# NUC029AE_v1 register map
File version: 1.0
Registers are 32-bit, read-write, reset 0x0 unless marked. A register's access mark holds for its fields unless they carry their own. Offsets are from the block's base; [hi:lo] are bit positions; 'fields as' and 'values as' point back to an identical list.

## TMR — TMR Register Map
Base 0x40010000
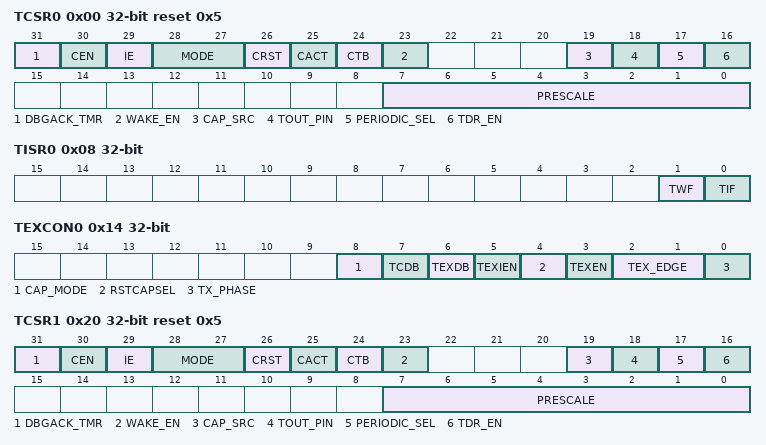
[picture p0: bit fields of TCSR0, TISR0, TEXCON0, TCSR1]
0x00 TCSR0 reset 0x5 — Timer0 Control and Status Register
  [31] DBGACK_TMR — ICE Debug Mode Acknowledge Disable Control (Write Protect). Timer counter will keep going no matter CPU is held by ICE or not.
    0=ICE debug mode acknowledgement effects TIMER counting; 1=ICE debug mode acknowledgement Disabled
  [30] CEN — Timer Enable Control
    0=Stops/Suspends counting; 1=Starts counting
  [29] IE — Interrupt Enable Control. If this bit is enabled, when the timer interrupt flag (TIF) is set to 1, the timer interrupt signal is generated and inform to CPU.
    0=Timer Interrupt function Disabled; 1=Timer Interrupt function Enabled
  [28:27] MODE — Timer Operating Mode
  [26] CRST — Timer Reset
    0=No effect; 1=Reset 8-bit prescale counter, 24-bit up counter value and CEN bit if CACT is 1
  [25] CACT ro — Timer Active Status (Read Only). This bit indicates the 24-bit up counter status.
    0=24-bit up counter is not active; 1=24-bit up counter is active
  [24] CTB — Counter Mode Enable Control. This bit is for external counting pin function enabled. When timer is used as an event counter, this bit should be set to 1 and select HCLK as timer clock source. Please refer to section 6.12.5.3 for detail description.
    0=External event counter mode Disabled; 1=External event counter mode Enabled
  [23] WAKE_EN — Wake-Up Enable Control. When WAKE_EN (UA_IER[6]) is set and the TIF or TEXIF (TEXISR[0]) is set, the timer controller will generator a wake-up trigger event to CPU.
    0=Wake-up trigger event Disabled; 1=Wake-up trigger event Enabled
  [19] CAP_SRC — Capture Pin Source Selection
    0=Capture Function source is from TxEX pin; 1=Capture Function source is from ACMPx output signal
  [18] TOUT_PIN — Toggle Out Pin Selection. When Timer is set to toggle mode,
    0=Time0/1 toggle output pin is T0/T1 pin; 1=Time0/1 toggle output pin is T0EX/T1EX pin
  [17] PERIODIC_SEL — Periodic Mode Behavior Selection
    0=In One-shot or Periodic mode, when write new TCMP, timer counter will reset; 1=In One-shot or Periodic mode, when write new TCMP if new TCMP TDR(current counter) , timer counter keep counting and will not reset. If new TCMP = TDR(current counter) , timer counter will reset
  [16] TDR_EN — Data Load Enable Control. When TDR_EN is set, TDR (Timer Data Register) will be updated continuously with the 24-bit up-timer value as the timer is counting.
    0=Timer Data Register update Disabled; 1=Timer Data Register update Enabled while Timer counter is active
  [7:0] PRESCALE — Prescale Counter
0x04 TCMPR0 — Timer0 Compare Register
  [23:0] TCMP — Timer Compared Value. TCMP is a 24-bit compared value register. When the internal 24-bit up counter value is equal to TCMP value, the TIF flag will set to 1. Note1: Never write 0x0 or 0x1 in TCMP field, or the core will run into unknown state.
0x08 TISR0 — Timer0 Interrupt Status Register
  [1] TWF — Timer Wake-up Flag. This bit indicates the interrupt wake-up flag status of Time. Note: This bit is cleared by writing 1 to it.
    0=Timer does not cause chip wake-up; 1=Chip wake-up from Idle or Power-down mode if Timer time-out interrupt signal generated
  [0] TIF — Timer Interrupt Flag. This bit indicates the interrupt flag status of Timer while TDR value reaches to TCMP value. Note: This bit is cleared by writing 1 to it.
    0=No effect; 1=TDR value matches the TCMP value
0x0C TDR0 ro — Timer0 Data Register
  [23:0] TDR — Timer Data Register. If TDR_EN (TCSRx[16]) is set to 1, TDR register value will be updated continuously to monitor 24-bit up counter value.
0x10 TCAP0 ro — Timer0 Capture Data Register
  [23:0] TCAP — Timer Capture Data Register. When TEXIF flag is set to 1, the current TDR value will be auto-loaded into this TCAP filed immediately.
0x14 TEXCON0 — Timer0 External Control Register
  [8] CAP_MODE — Capture Mode Selection
    0=Timer counter reset function or free-counting mode of timer capture function; 1=Trigger-counting mode of timer capture function
  [7] TCDB — Timer External Counter Input Pin De-bounce Enable Control
    0=Tx (x = 0~1) pin de-bounce Disabled; 1=Tx (x = 0~1) pin de-bounce Enabled
  [6] TEXDB — Timer External Capture Input Pin De-bounce Enable Control
    0=TxEX (x = 0~1) pin de-bounce Disabled; 1=TxEX (x = 0~1) pin de-bounce Enabled
  [5] TEXIEN — Timer External Capture Interrupt Enable Control. If TEXIEN enabled, Timer will raise an external capture interrupt signal and inform to CPU while TEXIF flag is set to 1.
    0=TxEX (x = 0~1) pin detection Interrupt Disabled; 1=TxEX (x = 0~1) pin detection Interrupt Enabled
  [4] RSTCAPSEL — Timer External Reset Counter / Timer External Capture Mode Selection
    0=Transition on TxEX (x = 0~1) pin is using to save the TDR value into TCAP value if TEXIF flag is set to 1; 1=Transition on TxEX (x = 0~1) pin is using to reset the 24-bit up counter
  [3] TEXEN — Timer External Pin Function Enable Control
    0=RSTCAPSEL function of TxEX (x = 0~1) pin will be ignored; 1=RSTCAPSEL function of TxEX (x = 0~1) pin is active
  [2:1] TEX_EDGE — Timer External Pin Edge Detection
    0=A 1 to 0 transition on TxEX (x = 0~1) will be detected; 1=A 0 to 1 transition on TxEX (x = 0~1) will be detected; 2=Either 1 to 0 or 0 to 1 transition on TxEX (x = 0~1) will be detected
  [0] TX_PHASE — Timer External Count Pin Phase Detect Selection
    0=A falling edge of Tx (x = 0~1) pin will be counted; 1=A rising edge of Tx (x = 0~1) pin will be counted
0x18 TEXISR0 — Timer0 External Interrupt Status Register
  [0] TEXIF — Timer External Interrupt Flag. This bit indicates the external capture interrupt flag status. Note: This bit is cleared by writing 1 to it
    0=TxEX (x = 0, 1) pin interrupt did not occur; 1=TxEX (x = 0, 1) pin interrupt occurred
0x20 TCSR1 reset 0x5 — Timer1 Control and Status Register
  fields as TCSR0
0x24 TCMPR1 — Timer1 Compare Register
  fields as TCMPR0
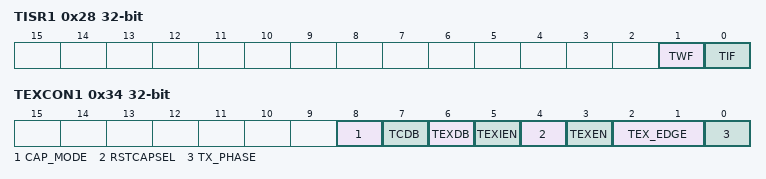
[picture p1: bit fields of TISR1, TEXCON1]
0x28 TISR1 — Timer1 Interrupt Status Register
  fields as TISR0
0x2C TDR1 ro — Timer1 Data Register
  fields as TDR0
0x30 TCAP1 ro — Timer1 Capture Data Register
  fields as TCAP0
0x34 TEXCON1 — Timer1 External Control Register
  fields as TEXCON0
0x38 TEXISR1 — Timer1 External Interrupt Status Register
  fields as TEXISR0
